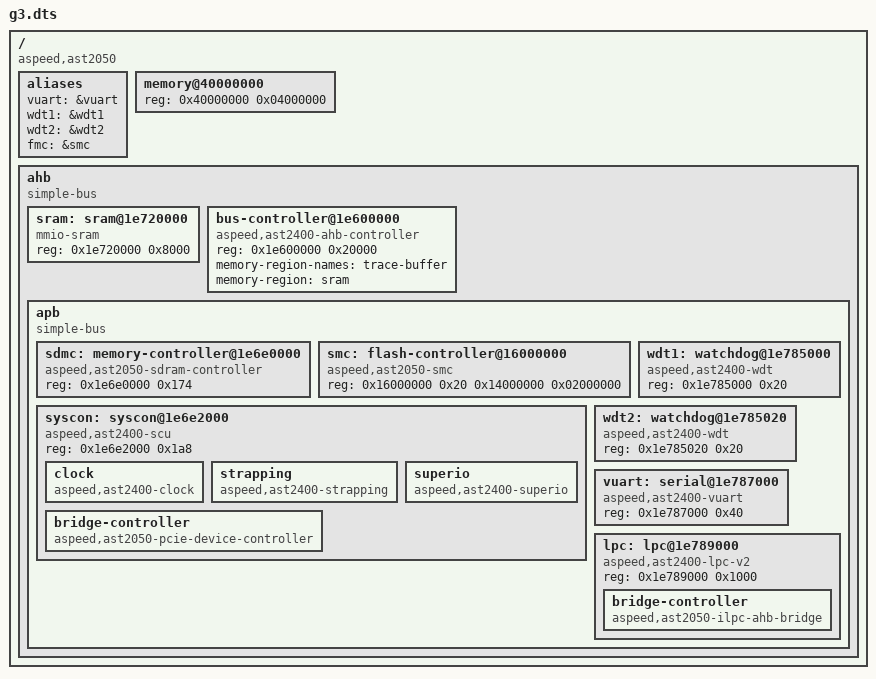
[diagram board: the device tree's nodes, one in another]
// SPDX-License-Identifier: Apache-2.0
// Copyright 2026 Tim Ansell

/dts-v1/;

/*
 * ASPEED AST2050 / AST1100 (G3) device tree for culvert.
 *
 * The AST2050 predates mainline and culvert's original G4/G5/G6 support. It is
 * register-compatible enough with the AST2400 (G4) that this repo already builds
 * its Linux device tree on aspeed-g4.dtsi, so the peripheral nodes below reuse
 * the "aspeed,ast2400-*" bindings (which is what selects culvert's existing
 * drivers) while the top-level compatible identifies the SoC as an AST2050.
 *
 * Differences from the AST2400 that still need dedicated handling are called out
 * inline (DDR2 memory controller, P2A register layout). The AST2050 has NO
 * hardware UART debug bridge (that is AST2500-only), so no debug bridge node.
 *
 * Register bases verified against the in-repo AST2050/AST1100 A3 datasheet and
 * asus-kgpe-d16-firmware/{ast2050.h,hwreg.h}.
 */

/ {
	compatible = "aspeed,ast2050", "aspeed,ast2400";
	#address-cells = <1>;
	#size-cells = <1>;

	aliases {
		vuart = &vuart;
		wdt1 = &wdt1;
		wdt2 = &wdt2;
		/*
		 * culvert's read/write commands look up the boot flash by the
		 * "fmc" alias. On the AST2050 that is the legacy SMC's CE2
		 * (boot SPI NOR), so point "fmc" at the SMC node below.
		 */
		fmc = &smc;
		/*
		 * No jtag alias: the AST2050 has no internal JTAG master. Its
		 * datasheet documents only an external ICE debug interface
		 * (§2.1) and has nothing at 0x1e6e4000 (register bases jump
		 * 0x1e6e2000 SCU -> 0x1e6e3000). culvert's software JTAG
		 * (internal JTAG master routed to the ARM via SCU MISC_CTRL) is
		 * an AST2400+ feature. AST2050 ARM debug uses the external
		 * AST_JTAG1 header + OpenOCD (see RPI4-OPENOCD-JTAG-WIRING.md).
		 */
	};

	// AST2050: 64 MB DDR2 at 0x40000000 on the boards we target
	// (KGPE-D16 / C410X), per PHYS_SDRAM_1_SIZE = 0x4000000 in
	// asus-kgpe-d16-firmware/ast2050.h. This is only the fallback span:
	// sdmc_get_dram() overrides the length from the live MCR04 geometry
	// decode (see the aspeed,ast2050-sdram-controller node below).
	memory@40000000 {
		device_type = "memory";
		reg = <0x40000000 0x04000000>;
	};

	ahb {
		compatible = "simple-bus";
		#address-cells = <1>;
		#size-cells = <1>;
		ranges;

		sram: sram@1e720000 {
			compatible = "mmio-sram";
			reg = <0x1e720000 0x8000>;	// 32K
		};

		bus-controller@1e600000 {
			compatible = "aspeed,ast2400-ahb-controller";
			reg = <0x1e600000 0x20000>;

			memory-region-names = "trace-buffer";
			memory-region = <&sram>;
		};

		apb {
			compatible = "simple-bus";
			#address-cells = <1>;
			#size-cells = <1>;

			// AST2050 SDMC is a DDR2 controller (not DDR3 as on the
			// AST2400). The MCR04 geometry fields sit at different bit
			// positions than the AST2400 (capacity [3:2], VGA [5:4]),
			// so use the dedicated aspeed,ast2050-sdram-controller
			// binding that decodes them (src/soc/sdmc.c). e.g. Raptor's
			// MCR04 = 0x585 -> 64 MB, not the 128 MB the AST2400 path gives.
			sdmc: memory-controller@1e6e0000 {
				compatible = "aspeed,ast2050-sdram-controller";
				reg = <0x1e6e0000 0x174>;
			};

			// Legacy SMC (SPI flash controller), datasheet section 11.
			// Control block at 0x16000000; the boot SPI NOR is on CE2,
			// data-mapped at 0x14000000 (= PHYS_FLASH_1 in
			// asus-kgpe-d16-firmware/ast2050.h), a 32 MB segment per
			// SMC00 = 0x240. This is NOT the AST2400 FMC (0x1e620000,
			// data 0x20000000); src/soc/sfc.c drives it via a dedicated
			// aspeed,ast2050-smc (legacy user-mode) path. reg index 0 =
			// control block, index 1 = CE2 flash data window.
			smc: flash-controller@16000000 {
				compatible = "aspeed,ast2050-smc";
				reg = <0x16000000 0x20
				       0x14000000 0x02000000>;
			};

			syscon: syscon@1e6e2000 {
				compatible = "aspeed,ast2400-scu", "syscon", "simple-mfd";
				reg = <0x1e6e2000 0x1a8>;

				clock {
					compatible = "aspeed,ast2400-clock";
				};

				strapping {
					compatible = "aspeed,ast2400-strapping";
				};

				superio {
					compatible = "aspeed,ast2400-superio";
				};

				// AST2050 P2A posture. Unlike the G4/G5/G6 pciectl
				// (which reads the SCU PCIe-config register SCU180 +
				// per-region write filters, none of which exist on G3),
				// the aspeed,ast2050-pcie-device-controller path reports
				// the P2A (PCI-slave -> AHB) bridge posture from the single
				// BMC-side gate SCU2C[8] "Disable PCI slave to AHB bus
				// bridge" (0 = enabled; datasheet section 18.2). The
				// host-side P2A00 protection key lives in host PCI-config
				// space (MMIOBASE+F000h, datasheet section 36), not the BMC
				// AHB, so only SCU2C[8] is checkable from the BMC side. The
				// P2A *transport* is separate (host-side bridge/p2a.c).
				bridge-controller {
					compatible = "aspeed,ast2050-pcie-device-controller", "bridge-controller";
				};
			};

			// No jtag@1e6e4000 node: absent on the AST2050 (see the
			// aliases comment above) -- external ICE debug only.

			wdt1: watchdog@1e785000 {
				compatible = "aspeed,ast2400-wdt";
				reg = <0x1e785000 0x20>;
			};

			wdt2: watchdog@1e785020 {
				compatible = "aspeed,ast2400-wdt";
				reg = <0x1e785020 0x20>;
			};

			vuart: serial@1e787000 {
				compatible = "aspeed,ast2400-vuart";
				reg = <0x1e787000 0x40>;
			};

			// LPC-to-AHB bridge (iLPC2AHB): HICR5[8] ENL2H etc.
			// (datasheet HICR5-8) -- present on the AST2050.
			lpc: lpc@1e789000 {
				compatible = "aspeed,ast2400-lpc-v2", "syscon", "simple-mfd";
				reg = <0x1e789000 0x1000>;

				bridge-controller {
					compatible = "aspeed,ast2050-ilpc-ahb-bridge", "bridge-controller";
				};
			};
		};
	};
};
